# STM32U585xx register map
File version: 1.0
Registers are 32-bit, read-write, reset 0x0 unless marked. A register's access mark holds for its fields unless they carry their own. Offsets are from the block's base; [hi:lo] are bit positions; {n}, {i} and the like mark numbered series; 'fields as' and 'values as' point back to an identical list.

## OTFDEC1
Base 0x420C5000
Same registers: OTFDEC2 0x420C5400, OTFDEC1_S 0x520C5000, OTFDEC2_S 0x520C5400
0x00 CR — OTFDEC Control register
  [0] ENC — Encryption mode bit
0x10 PRIVCFGR — OTFDEC Privileged access control Configuration register
  [0] PRIV — Privileged access protection
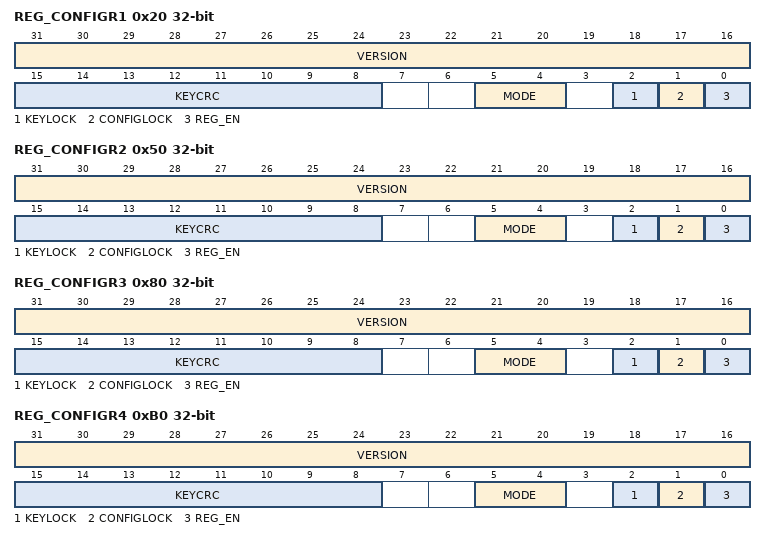
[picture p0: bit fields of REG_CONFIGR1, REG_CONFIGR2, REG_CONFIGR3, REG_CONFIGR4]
0x20 REG_CONFIGR1 — OTFDEC Region Configuration register
  [31:16] VERSION — Region firmware version
  [15:8] KEYCRC — Region key 8-bit CRC
  [5:4] MODE — Region operating mode
  [2] KEYLOCK — Region key lock
  [1] CONFIGLOCK — Region config lock
  [0] REG_EN — Region on-the-fly decryption enable
0x24 REG_START_ADDR1 — OTFDEC Region Start Address register
  [31:0] REG_START_ADDR — Region AHB start address
0x28 REG_END_ADDR1 — OTFDEC Region End Address register
  [31:0] REG_END_ADDR — Region AHB end address
0x2C REG_NONCER01 — OTFDEC Region Nonce register 0
  [31:0] REG_NONCER0 — Region Nonce Register (LSB nonce[31:0])
0x30 REG_NONCER1 — OTFDEC Region Nonce register 1
  [31:0] REG_NONCER1 — Region Nonce Register (MSB nonce[63:32])
{0x4+0x30*i} REG_KEYR{i:02} (i=1..4) — OTFDEC Region Key register 0
  [31:0] REG_KEYR0 — Region Key Register (LSB key[31:0])
{0x4+0x34*i} REG_KEYR{i} (i=1..3) — OTFDEC Region Key register {i}
  [31:0] REG_KEYR{i} — Region Key Register (key[{32i+31}:{32i}])
0x3C REG_KEYR21 — OTFDEC Region Key register 2
  [31:0] REG_KEYR2 — Region Key Register (key[95:64])
0x40 REG_KEYR31 — OTFDEC Region Key register 3
  [31:0] REG_KEYR3 — Region Key Register (key[127:96])
0x50 REG_CONFIGR2 — OTFDEC Region Configuration register
  fields as REG_CONFIGR1
0x54 REG_START_ADDR2 — OTFDEC Region Start Address register
  [31:0] REG_START_ADDR — Region AHB start address
0x58 REG_END_ADDR2 — OTFDEC Region End Address register
  [31:0] REG_END_ADDR — Region AHB end address
0x5C REG_NONCER02 — OTFDEC Region Nonce register 0
  [31:0] REG_NONCER0 — Region Nonce Register (LSB nonce[31:0])
0x60 REG_NONCER12 — OTFDEC Region Nonce register 1
  [31:0] REG_NONCER1 — Region Nonce Register (MSB nonce[63:32])
0x68 REG_KEYR12 — OTFDEC Region Key register 1
  [31:0] REG_KEYR1 — Region Key Register (key[63:32])
0x70 REG_KEYR32 — OTFDEC Region Key register 3
  [31:0] REG_KEYR3 — Region Key Register (key[127:96])
0x80 REG_CONFIGR3 — OTFDEC Region Configuration register
  fields as REG_CONFIGR1
0x84 REG_START_ADDR3 — OTFDEC Region Start Address register
  [31:0] REG_START_ADDR — Region AHB start address
0x88 REG_END_ADDR3 — OTFDEC Region End Address register
  [31:0] REG_END_ADDR — Region AHB end address
0x8C REG_NONCER03 — OTFDEC Region Nonce register 0
  [31:0] REG_NONCER0 — Region Nonce Register (LSB nonce[31:0])
0x90 REG_NONCER13 — OTFDEC Region Nonce register 1
  [31:0] REG_NONCER1 — Region Nonce Register (MSB nonce[63:32])
0x98 REG_KEYR13 — OTFDEC Region Key register 1
  [31:0] REG_KEYR1 — Region Key Register (key[63:32])
0x9C REG_KEYR23 — OTFDEC Region Key register 2
  [31:0] REG_KEYR2 — Region Key Register (key[95:64])
0xB0 REG_CONFIGR4 — OTFDEC Region Configuration register
  fields as REG_CONFIGR1
0xB4 REG_START_ADDR4 — OTFDEC Region Start Address register
  [31:0] REG_START_ADDR — Region AHB start address
0xB8 REG_END_ADDR4 — OTFDEC Region End Address register
  [31:0] REG_END_ADDR — Region AHB end address
0xBC REG_NONCER04 — OTFDEC Region Nonce register 0
  [31:0] REG_NONCER0 — Region Nonce Register (LSB nonce[31:0])
0xC0 REG_NONCER14 — OTFDEC Region Nonce register 1
  [31:0] REG_NONCER1 — Region Nonce Register (MSB nonce[63:32])
0xC8 REG_KEYR14 — OTFDEC Region Key register 1
  [31:0] REG_KEYR1 — Region Key Register (key[63:32])
0xCC REG_KEYR24 — OTFDEC Region Key register 2
  [31:0] REG_KEYR2 — Region Key Register (key[95:64])
0xD0 REG_KEYR34 — OTFDEC Region Key register 3
  [31:0] REG_KEYR3 — Region Key Register (key[127:96])
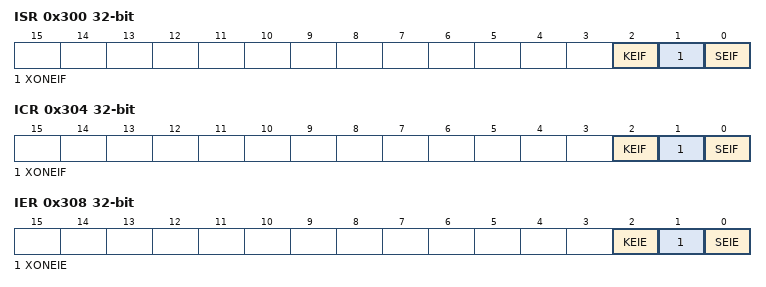
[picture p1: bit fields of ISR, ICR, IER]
0x300 ISR — OTFDEC Interrupt Status register
  [2] KEIF — Key Error Interrupt Flag status bit before enable (mask)
  [1] XONEIF — Execute-only Error Interrupt Flag status bit before enable (mask)
  [0] SEIF — Security Error Interrupt Flag status bit before enable (mask)
0x304 ICR — OTFDEC Interrupt Clear register
  [2] KEIF — Key Error Interrupt Flag clear bit
  [1] XONEIF — Execute-only Error Interrupt Flag clear bit
  [0] SEIF — Security Error Interrupt Flag clear bit
0x308 IER — OTFDEC Interrupt Enable register
  [2] KEIE
  [1] XONEIE — Execute-only Error Interrupt Enable bit
  [0] SEIE — Security Error Interrupt Enable bit
